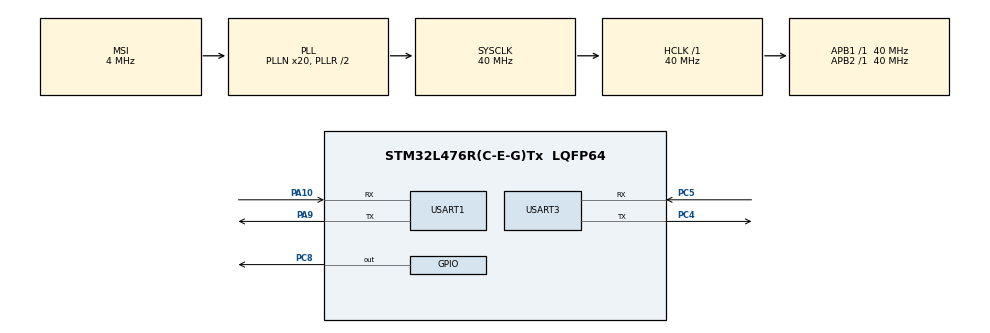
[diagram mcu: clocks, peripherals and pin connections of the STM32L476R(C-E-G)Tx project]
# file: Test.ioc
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Mcu.Family=STM32L4
Mcu.Name=STM32L476R(C-E-G)Tx
Mcu.Package=LQFP64
NVIC.PriorityGroup=NVIC_PRIORITYGROUP_4
NVIC.RCC_IRQn=true\:0\:0\:true\:false\:true\:true
NVIC.USART1_IRQn=true\:3\:0\:true\:false\:true\:true
NVIC.USART3_IRQn=true\:1\:0\:true\:false\:true\:true
PA10.Mode=Asynchronous
PA10.Signal=USART1_RX
PA13\ (JTMS-SWDIO).Mode=Serial_Wire
PA13\ (JTMS-SWDIO).Signal=SYS_JTMS-SWDIO
PA14\ (JTCK-SWCLK).Mode=Serial_Wire
PA14\ (JTCK-SWCLK).Signal=SYS_JTCK-SWCLK
PA9.Mode=Asynchronous
PA9.Signal=USART1_TX
PC4.Mode=Asynchronous
PC4.Signal=USART3_TX
PC5.Mode=Asynchronous
PC5.Signal=USART3_RX
PC8.GPIO_ModeDefaultOutputPP=GPIO_MODE_OUTPUT_PP
PC8.GPIO_PuPd=GPIO_PULLUP
PC8.GPIO_Speed=GPIO_SPEED_FREQ_LOW
PC8.PinState=GPIO_PIN_RESET
PC8.Signal=GPIO_Output
PH0-OSC_IN\ (PH0).Mode=HSE-External-Oscillator
PH0-OSC_IN\ (PH0).Signal=RCC_OSC_IN
PH1-OSC_OUT\ (PH1).Mode=HSE-External-Oscillator
PH1-OSC_OUT\ (PH1).Signal=RCC_OSC_OUT
ProjectManager.HeapSize=0x200
ProjectManager.StackSize=0x400
ProjectManager.TargetToolchain=MDK-ARM V5
RCC.AHBFreq_Value=40000000
RCC.APB1Freq_Value=40000000
RCC.APB1TimFreq_Value=40000000
RCC.APB2Freq_Value=40000000
RCC.APB2TimFreq_Value=40000000
RCC.CortexFreq_Value=40000000
RCC.HCLKFreq_Value=40000000
RCC.HSE_VALUE=8000000
RCC.HSI_VALUE=16000000
RCC.MSI_VALUE=4000000
RCC.PLLN=20
RCC.SYSCLKFreq_VALUE=40000000
RCC.SYSCLKSource=RCC_SYSCLKSOURCE_PLLCLK
RCC.VCOOutputFreq_Value=80000000
USART1.VirtualMode-Asynchronous=VM_ASYNC
USART1.WordLength=WORDLENGTH_8B
USART3.VirtualMode-Asynchronous=VM_ASYNC
USART3.WordLength=WORDLENGTH_8B
board=Test

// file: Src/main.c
/**
  ******************************************************************************
  * File Name          : main.c
  * Description        : Main program body
  ******************************************************************************
  ** This notice applies to any and all portions of this file
  * that are not between comment pairs USER CODE BEGIN and
  * USER CODE END. Other portions of this file, whether
  * inserted by the user or by software development tools
  * are owned by their respective copyright owners.
  *
  * COPYRIGHT(c) 2019 STMicroelectronics
  *
  * Redistribution and use in source and binary forms, with or without modification,
  * are permitted provided that the following conditions are met:
  *   1. Redistributions of source code must retain the above copyright notice,
  *      this list of conditions and the following disclaimer.
  *   2. Redistributions in binary form must reproduce the above copyright notice,
  *      this list of conditions and the following disclaimer in the documentation
  *      and/or other materials provided with the distribution.
  *   3. Neither the name of STMicroelectronics nor the names of its contributors
  *      may be used to endorse or promote products derived from this software
  *      without specific prior written permission.
  *
  * THIS SOFTWARE IS PROVIDED BY THE COPYRIGHT HOLDERS AND CONTRIBUTORS "AS IS"
  * AND ANY EXPRESS OR IMPLIED WARRANTIES, INCLUDING, BUT NOT LIMITED TO, THE
  * IMPLIED WARRANTIES OF MERCHANTABILITY AND FITNESS FOR A PARTICULAR PURPOSE ARE
  * DISCLAIMED. IN NO EVENT SHALL THE COPYRIGHT HOLDER OR CONTRIBUTORS BE LIABLE
  * FOR ANY DIRECT, INDIRECT, INCIDENTAL, SPECIAL, EXEMPLARY, OR CONSEQUENTIAL
  * DAMAGES (INCLUDING, BUT NOT LIMITED TO, PROCUREMENT OF SUBSTITUTE GOODS OR
  * SERVICES; LOSS OF USE, DATA, OR PROFITS; OR BUSINESS INTERRUPTION) HOWEVER
  * CAUSED AND ON ANY THEORY OF LIABILITY, WHETHER IN CONTRACT, STRICT LIABILITY,
  * OR TORT (INCLUDING NEGLIGENCE OR OTHERWISE) ARISING IN ANY WAY OUT OF THE USE
  * OF THIS SOFTWARE, EVEN IF ADVISED OF THE POSSIBILITY OF SUCH DAMAGE.
  *
  ******************************************************************************
  */
#include "main.h"
#include "stm32l4xx_hal.h"
#include "string.h"
#include "B8_ONE.h"

UART_HandleTypeDef huart1;
UART_HandleTypeDef huart3;

/* USER CODE BEGIN PV */
/* Private variables ---------------------------------------------------------*/

	uint8_t str;
/* USER CODE END PV */

void SystemClock_Config(void);
static void MX_GPIO_Init(void);
static void MX_USART1_UART_Init(void);
static void MX_USART3_UART_Init(void);

/* USER CODE BEGIN PFP */
/* Private function prototypes -----------------------------------------------*/

/* USER CODE END PFP */

int main(void){

	char* objid="3311";
	char* insBitmap="1";
	char 	actCount=2;				//可执行资源计数
	char	attrCount=4;			//可读\可写资源计数
	static char* msgid;
	char* resid="5706";
	char* vlestr="5706";

  /* MCU Configuration----------------------------------------------------------*/

  /* Reset of all peripherals, Initializes the Flash interface and the Systick. */
  HAL_Init();

  /* Configure the system clock */
  SystemClock_Config();

  /* Initialize all configured peripherals */
  MX_GPIO_Init();
  MX_USART1_UART_Init();
  MX_USART3_UART_Init();
	memset(USART3_RX_BUF,0,sizeof(USART3_RX_BUF));usart3_rcv_len=0;
	HAL_UART_Receive_IT(&huart3,&str,1);
  /* USER CODE BEGIN 2 */
	on_line(&huart3,objid,msgid,insBitmap,vlestr,attrCount,actCount);
  /* USER CODE END 2 */

  /* Infinite loop */
  while (1)
  {
		msgid=msgidch;
		send_message(&huart3,msgid,objid,0,resid,1,11,"\"helloworld!\"");
		HAL_Delay(5000);
  }

}

/** System Clock Configuration
*/
void SystemClock_Config(void)
{

  RCC_OscInitTypeDef RCC_OscInitStruct;
  RCC_ClkInitTypeDef RCC_ClkInitStruct;
  RCC_PeriphCLKInitTypeDef PeriphClkInit;

    /**Initializes the CPU, AHB and APB busses clocks
    */
  RCC_OscInitStruct.OscillatorType = RCC_OSCILLATORTYPE_MSI;
  RCC_OscInitStruct.MSIState = RCC_MSI_ON;
  RCC_OscInitStruct.MSICalibrationValue = 0;
  RCC_OscInitStruct.MSIClockRange = RCC_MSIRANGE_6;
  RCC_OscInitStruct.PLL.PLLState = RCC_PLL_ON;
  RCC_OscInitStruct.PLL.PLLSource = RCC_PLLSOURCE_MSI;
  RCC_OscInitStruct.PLL.PLLN = 20;
  RCC_OscInitStruct.PLL.PLLP = RCC_PLLP_DIV7;
  RCC_OscInitStruct.PLL.PLLQ = RCC_PLLQ_DIV2;
  RCC_OscInitStruct.PLL.PLLR = RCC_PLLR_DIV2;
  if (HAL_RCC_OscConfig(&RCC_OscInitStruct) != HAL_OK)
  {
    _Error_Handler(__FILE__, __LINE__);
  }

    /**Initializes the CPU, AHB and APB busses clocks
    */
  RCC_ClkInitStruct.ClockType = RCC_CLOCKTYPE_HCLK|RCC_CLOCKTYPE_SYSCLK
                              |RCC_CLOCKTYPE_PCLK1|RCC_CLOCKTYPE_PCLK2;
  RCC_ClkInitStruct.SYSCLKSource = RCC_SYSCLKSOURCE_PLLCLK;
  RCC_ClkInitStruct.AHBCLKDivider = RCC_SYSCLK_DIV1;
  RCC_ClkInitStruct.APB1CLKDivider = RCC_HCLK_DIV1;
  RCC_ClkInitStruct.APB2CLKDivider = RCC_HCLK_DIV1;

  if (HAL_RCC_ClockConfig(&RCC_ClkInitStruct, FLASH_LATENCY_1) != HAL_OK)
  {
    _Error_Handler(__FILE__, __LINE__);
  }

  PeriphClkInit.PeriphClockSelection = RCC_PERIPHCLK_USART1|RCC_PERIPHCLK_USART3;
  PeriphClkInit.Usart1ClockSelection = RCC_USART1CLKSOURCE_PCLK2;
  PeriphClkInit.Usart3ClockSelection = RCC_USART3CLKSOURCE_PCLK1;
  if (HAL_RCCEx_PeriphCLKConfig(&PeriphClkInit) != HAL_OK)
  {
    _Error_Handler(__FILE__, __LINE__);
  }

    /**Configure the main internal regulator output voltage
    */
  if (HAL_PWREx_ControlVoltageScaling(PWR_REGULATOR_VOLTAGE_SCALE1) != HAL_OK)
  {
    _Error_Handler(__FILE__, __LINE__);
  }

    /**Configure the Systick interrupt time
    */
  HAL_SYSTICK_Config(HAL_RCC_GetHCLKFreq()/1000);

    /**Configure the Systick
    */
  HAL_SYSTICK_CLKSourceConfig(SYSTICK_CLKSOURCE_HCLK);

  /* SysTick_IRQn interrupt configuration */
  HAL_NVIC_SetPriority(SysTick_IRQn, 0, 0);
}

/* USART1 init function */
static void MX_USART1_UART_Init(void)
{

  huart1.Instance = USART1;
  huart1.Init.BaudRate = 115200;
  huart1.Init.WordLength = UART_WORDLENGTH_8B;
  huart1.Init.StopBits = UART_STOPBITS_1;
  huart1.Init.Parity = UART_PARITY_NONE;
  huart1.Init.Mode = UART_MODE_TX_RX;
  huart1.Init.HwFlowCtl = UART_HWCONTROL_NONE;
  huart1.Init.OverSampling = UART_OVERSAMPLING_16;
  huart1.Init.OneBitSampling = UART_ONE_BIT_SAMPLE_DISABLE;
  huart1.AdvancedInit.AdvFeatureInit = UART_ADVFEATURE_NO_INIT;
  if (HAL_UART_Init(&huart1) != HAL_OK)
  {
    _Error_Handler(__FILE__, __LINE__);
  }

}

/* USART3 init function */
static void MX_USART3_UART_Init(void)
{

  huart3.Instance = USART3;
  huart3.Init.BaudRate = 115200;
  huart3.Init.WordLength = UART_WORDLENGTH_8B;
  huart3.Init.StopBits = UART_STOPBITS_1;
  huart3.Init.Parity = UART_PARITY_NONE;
  huart3.Init.Mode = UART_MODE_TX_RX;
  huart3.Init.HwFlowCtl = UART_HWCONTROL_NONE;
  huart3.Init.OverSampling = UART_OVERSAMPLING_16;
  huart3.Init.OneBitSampling = UART_ONE_BIT_SAMPLE_DISABLE;
  huart3.AdvancedInit.AdvFeatureInit = UART_ADVFEATURE_NO_INIT;
  if (HAL_UART_Init(&huart3) != HAL_OK)
  {
    _Error_Handler(__FILE__, __LINE__);
  }

}

/** Configure pins as
        * Analog
        * Input
        * Output
        * EVENT_OUT
        * EXTI
*/
static void MX_GPIO_Init(void)
{

  GPIO_InitTypeDef GPIO_InitStruct;

  /* GPIO Ports Clock Enable */
  __HAL_RCC_GPIOH_CLK_ENABLE();
  __HAL_RCC_GPIOC_CLK_ENABLE();
  __HAL_RCC_GPIOA_CLK_ENABLE();

  /*Configure GPIO pin Output Level */
  HAL_GPIO_WritePin(GPIOC, GPIO_PIN_8, GPIO_PIN_RESET);

  /*Configure GPIO pin : PC8 */
  GPIO_InitStruct.Pin = GPIO_PIN_8;
  GPIO_InitStruct.Mode = GPIO_MODE_OUTPUT_PP;
  GPIO_InitStruct.Pull = GPIO_PULLUP;
  GPIO_InitStruct.Speed = GPIO_SPEED_FREQ_LOW;
  HAL_GPIO_Init(GPIOC, &GPIO_InitStruct);

}

/* USER CODE BEGIN 4 */

void HAL_UART_RxCpltCallback(UART_HandleTypeDef *huart)
{
//	 if(huart->Instance == USART1)
//    {
//        HAL_UART_Transmit(&huart1,&str,1,100);

//        HAL_UART_Receive_IT(&huart1,&str,1);
//    }
    if(huart->Instance == USART3)
    {
//       HAL_UART_Transmit(&huart3,&str,1,0);
				USART3_RX_BUF[usart3_rcv_len]=str;usart3_rcv_len++;
				if(usart3_rcv_len>=127)usart3_rcv_len=0;
        HAL_UART_Receive_IT(&huart3,&str,1);
    }
}

/* USER CODE END 4 */

void _Error_Handler(char * file, int line)
{
  while(1)
  {
  }
}

/************************ (C) COPYRIGHT STMicroelectronics *****END OF FILE****/
